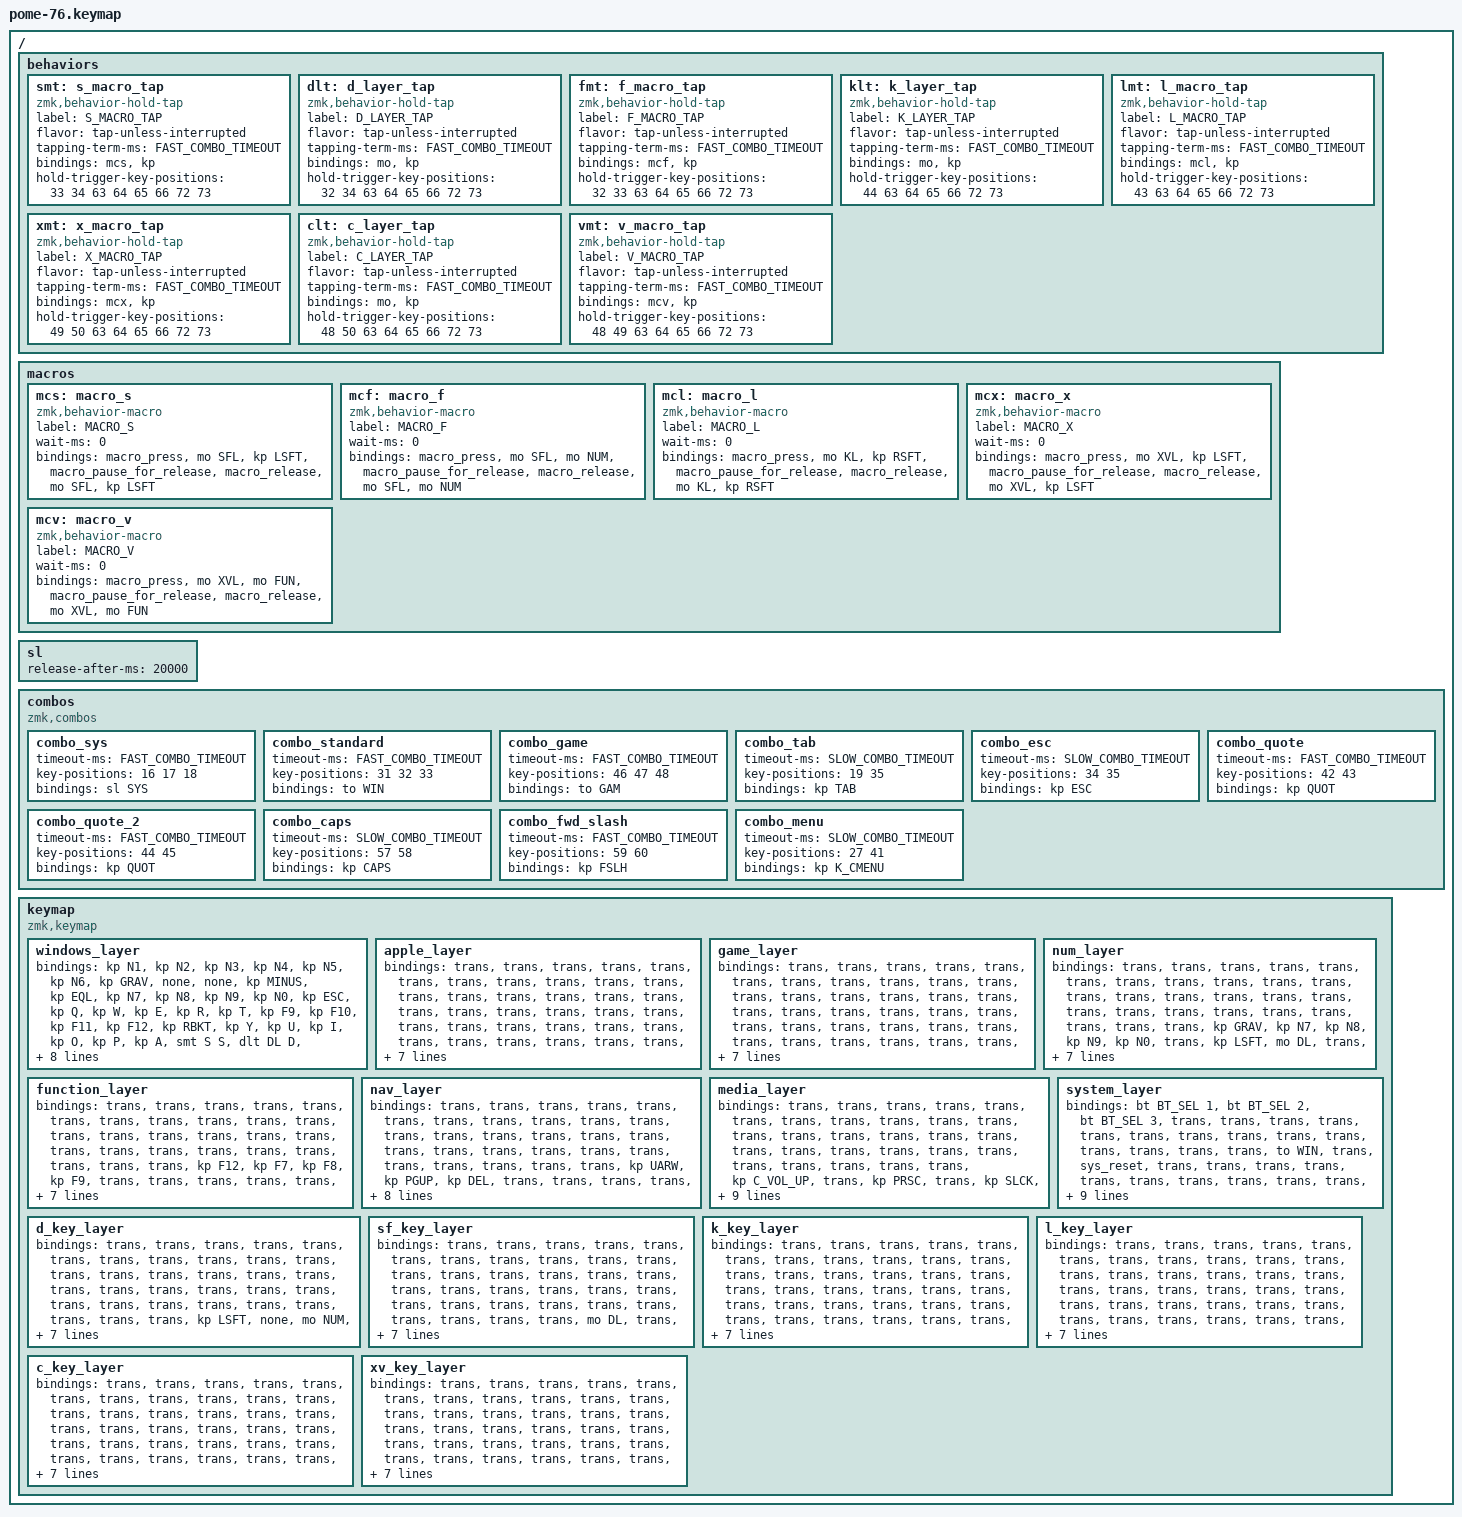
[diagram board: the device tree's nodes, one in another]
#include <behaviors.dtsi>
#include <dt-bindings/zmk/bt.h>
#include <dt-bindings/zmk/keys.h>
#include <dt-bindings/zmk/outputs.h>

// Layers ENUM
#define WIN 0     // Windows
#define APL 1     // Apple
#define GAM 2     // Gaming
#define NUM 3     // Numbers
#define FUN 4     // Function (F-keys)
#define NAV 5     // Navigation
#define MED 6     // Media
#define SYS 7     // System
#define DL  8     // D-Layer
#define SFL 9     // S/F-Layer
#define KL  10    // K-Layer
#define LL  11    // L-Layer
#define CL  12    // C-Layer
#define XVL 13    // X/V-Layer

// See mercury-u.keymap for the early history of timeout values.
// 12Nov2023
// The word "sounds" still rarely comes out as "soundSHIFT", so let's decrease timeout from 50ms to 35ms.
//#define FAST_COMBO_TIMEOUT 35
#define FAST_COMBO_TIMEOUT 1000 // for testing purposes only, extend this to a long time.

// #define MEDIUM_COMBO_TIMEOUT 125
#define MEDIUM_COMBO_TIMEOUT 80

// SLOW_COMBO_TIMEOUT is a very, very long and lenient timeout, and should be mostly only used for combos
// involving keys that are pressed by the same finger (H & J for example).
#define SLOW_COMBO_TIMEOUT 200

/ {
    behaviors {};

    macros {
        mcs: macro_s {
            label = "MACRO_S";
            compatible = "zmk,behavior-macro";
            #binding-cells = <0>;
            wait-ms = <0>;
            bindings
                = <&macro_press &mo SFL &kp LSFT>
                , <&macro_pause_for_release>
                , <&macro_release &mo SFL &kp LSFT>
                ;
        };

        mcf: macro_f {
            label = "MACRO_F";
            compatible = "zmk,behavior-macro";
            #binding-cells = <0>;
            wait-ms = <0>;
            bindings
                = <&macro_press &mo SFL &mo NUM>
                , <&macro_pause_for_release>
                , <&macro_release &mo SFL &mo NUM>
                ;
        };

        mcl: macro_l {
            label = "MACRO_L";
            compatible = "zmk,behavior-macro";
            #binding-cells = <0>;
            wait-ms = <0>;
            bindings
                = <&macro_press &mo KL &kp RSFT>
                , <&macro_pause_for_release>
                , <&macro_release &mo KL &kp RSFT>
                ;
        };

        mcx: macro_x {
            label = "MACRO_X";
            compatible = "zmk,behavior-macro";
            #binding-cells = <0>;
            wait-ms = <0>;
            bindings
                = <&macro_press &mo XVL &kp LSFT>
                , <&macro_pause_for_release>
                , <&macro_release &mo XVL &kp LSFT>
                ;
        };

        mcv: macro_v {
            label = "MACRO_V";
            compatible = "zmk,behavior-macro";
            #binding-cells = <0>;
            wait-ms = <0>;
            bindings
                = <&macro_press &mo XVL &mo FUN>
                , <&macro_pause_for_release>
                , <&macro_release &mo XVL &mo FUN>
                ;
        };
    };

    behaviors {
        // 63, 64, 65, and 66 are left hand modifier keys
        // 72 and 73 and right hand layer keys
        // 32 is S
        // 43 is K
        smt: s_macro_tap {
            compatible = "zmk,behavior-hold-tap";
            label = "S_MACRO_TAP";
            #binding-cells = <2>;
            flavor = "tap-unless-interrupted";
            tapping-term-ms = <FAST_COMBO_TIMEOUT>;
            bindings = <&mcs>, <&kp>;
            hold-trigger-key-positions = <33 34 63 64 65 66 72 73>;
        };

        dlt: d_layer_tap {
            compatible = "zmk,behavior-hold-tap";
            label = "D_LAYER_TAP";
            #binding-cells = <2>;
            flavor = "tap-unless-interrupted";
            tapping-term-ms = <FAST_COMBO_TIMEOUT>;
            bindings = <&mo>, <&kp>;
            hold-trigger-key-positions = <32 34 63 64 65 66 72 73>;
        };

        fmt: f_macro_tap {
            compatible = "zmk,behavior-hold-tap";
            label = "F_MACRO_TAP";
            #binding-cells = <2>;
            flavor = "tap-unless-interrupted";
            tapping-term-ms = <FAST_COMBO_TIMEOUT>;
            bindings = <&mcf>, <&kp>;
            hold-trigger-key-positions = <32 33 63 64 65 66 72 73>;
        };

        klt: k_layer_tap {
            compatible = "zmk,behavior-hold-tap";
            label = "K_LAYER_TAP";
            #binding-cells = <2>;
            flavor = "tap-unless-interrupted";
            tapping-term-ms = <FAST_COMBO_TIMEOUT>;
            bindings = <&mo>, <&kp>;
            hold-trigger-key-positions = <44 63 64 65 66 72 73>;
        };
        
        lmt: l_macro_tap {
            compatible = "zmk,behavior-hold-tap";
            label = "L_MACRO_TAP";
            #binding-cells = <2>;
            flavor = "tap-unless-interrupted";
            tapping-term-ms = <FAST_COMBO_TIMEOUT>;
            bindings = <&mcl>, <&kp>;
            hold-trigger-key-positions = <43 63 64 65 66 72 73>;
        };

        xmt: x_macro_tap {
            compatible = "zmk,behavior-hold-tap";
            label = "X_MACRO_TAP";
            #binding-cells = <2>;
            flavor = "tap-unless-interrupted";
            tapping-term-ms = <FAST_COMBO_TIMEOUT>;
            bindings = <&mcx>, <&kp>;
            hold-trigger-key-positions = <49 50 63 64 65 66 72 73>;
        };

        clt: c_layer_tap {
            compatible = "zmk,behavior-hold-tap";
            label = "C_LAYER_TAP";
            #binding-cells = <2>;
            flavor = "tap-unless-interrupted";
            tapping-term-ms = <FAST_COMBO_TIMEOUT>;
            bindings = <&mo>, <&kp>;
            hold-trigger-key-positions = <48 50 63 64 65 66 72 73>;
        };

        vmt: v_macro_tap {
            compatible = "zmk,behavior-hold-tap";
            label = "V_MACRO_TAP";
            #binding-cells = <2>;
            flavor = "tap-unless-interrupted";
            tapping-term-ms = <FAST_COMBO_TIMEOUT>;
            bindings = <&mcv>, <&kp>;
            hold-trigger-key-positions = <48 49 63 64 65 66 72 73>;
        };
    };

    sl {
        release-after-ms = <20000>; // 20 seconds
    };
    combos {
        compatible = "zmk,combos";

        combo_sys {
            timeout-ms = <FAST_COMBO_TIMEOUT>;
            key-positions = <16 17 18>;
            bindings = <&sl SYS>;
        };
        combo_standard {
            timeout-ms = <FAST_COMBO_TIMEOUT>;
            key-positions = <31 32 33>;
            bindings = <&to WIN>;
        };
        combo_game {
            timeout-ms = <FAST_COMBO_TIMEOUT>;
            key-positions = <46 47 48>;
            bindings = <&to GAM>;
        };

        // Slow combos: these combos exclusively use keys controlled by a single index-finger,
        // which makes them very unlikely to be accidentally triggered by a standard touch-typist
        // them during normal typing, even with a very long timeout.
        combo_tab {
            timeout-ms = <SLOW_COMBO_TIMEOUT>;
            key-positions = <19 35>; /* RG */
            bindings = <&kp TAB>;
        };
        combo_esc {
            timeout-ms = <SLOW_COMBO_TIMEOUT>;
            key-positions = <34 35>; /* FG */
            bindings = <&kp ESC>;
        };
        combo_quote {
            timeout-ms = <FAST_COMBO_TIMEOUT>;
            key-positions = <42 43>; /* JK */
            bindings = <&kp QUOT>;
        };
        combo_quote_2 {
            timeout-ms = <FAST_COMBO_TIMEOUT>;
            key-positions = <44 45>; /* L; */
            bindings = <&kp QUOT>;
        };
        combo_caps {
            timeout-ms = <SLOW_COMBO_TIMEOUT>;
            key-positions = <57 58>; /* NM */
            bindings = <&kp CAPS>;
        };
        combo_fwd_slash {
            timeout-ms = <FAST_COMBO_TIMEOUT>;
            // HU is a little hard to reach */
            key-positions = <59 60>; /* ,. */
            bindings = <&kp FSLH>;
        };
        combo_menu {
            timeout-ms = <SLOW_COMBO_TIMEOUT>;
            key-positions = <27 41>; /* UH */
            bindings = <&kp K_CMENU>;
        };
    };

    keymap {
        compatible = "zmk,keymap";

        windows_layer {
            bindings = <
              &kp N1        &kp N2        &kp N3        &kp N4        &kp N5        &kp N6        &kp GRAV      &none         &none         &kp MINUS     &kp EQL       &kp N7        &kp N8        &kp N9        &kp N0        &kp ESC
              &kp Q         &kp W         &kp E         &kp R         &kp T         &kp F9        &kp F10       &kp F11       &kp F12       &kp RBKT      &kp Y         &kp U         &kp I         &kp O         &kp P
              &kp A         &smt S S      &dlt DL D     &fmt F F      &kp G         &kp F5        &kp F6        &kp F7        &kp F8        &kp LBKT      &kp H         &kp J         &klt KL K     &lmt L L      &kp SCLN
&kp LSFT      &kp Z         &xmt X X      &clt CL C     &vmt V V      &kp B         &kp F1        &kp F2        &kp F3        &kp F4        &kp BSLH      &kp N         &kp M         &kp CMMA      &kp DOT
&kp ESC       &kp DEL       &kp LGUI      &none        &kp LCTL      &kp LALT      &none         &none         &none         &kp BSLH      &kp SPC       &mo NAV       &mo MED       &kp BKSP      &kp RET
            >;
        };
        
        apple_layer {
            bindings = <
              &trans        &trans        &trans        &trans        &trans        &trans        &trans        &trans        &trans        &trans        &trans        &trans        &trans        &trans        &trans        &trans
              &trans        &trans        &trans        &trans        &trans        &trans        &trans        &trans        &trans        &trans        &trans        &trans        &trans        &trans        &trans
              &trans        &trans        &trans        &trans        &trans        &trans        &trans        &trans        &trans        &trans        &trans        &trans        &trans        &trans        &trans
&trans        &trans        &trans        &trans        &trans        &trans        &trans        &trans        &trans        &trans        &trans        &trans        &trans        &trans        &trans
&trans        &trans        &trans        &kp LCTL      &kp LGUI      &kp LALT      &trans        &trans        &trans        &trans        &trans        &trans        &trans        &trans        &trans
            >;
        };

// game_layer is disabled (fully transparent) for now.
        game_layer {
            bindings = <
              &trans        &trans        &trans        &trans        &trans        &trans        &trans        &trans        &trans        &trans        &trans        &trans        &trans        &trans        &trans        &trans
              &trans        &trans        &trans        &trans        &trans        &trans        &trans        &trans        &trans        &trans        &trans        &trans        &trans        &trans        &trans
              &trans        &trans        &trans        &trans        &trans        &trans        &trans        &trans        &trans        &trans        &trans        &trans        &trans        &trans        &trans
&trans        &trans        &trans        &trans        &trans        &trans        &trans        &trans        &trans        &trans        &trans        &trans        &trans        &trans        &trans
&trans        &trans        &trans        &trans        &trans        &trans        &trans        &trans        &trans        &trans        &trans        &trans        &trans        &trans        &trans
            >;
        };

        num_layer {
            bindings = <
              &trans        &trans        &trans        &trans        &trans        &trans        &trans        &trans        &trans        &trans        &trans        &trans        &trans        &trans        &trans        &trans
              &trans        &trans        &trans        &trans        &trans        &trans        &trans        &trans        &trans        &trans        &kp GRAV      &kp N7        &kp N8        &kp N9        &kp N0
              &trans        &kp LSFT      &mo DL        &trans        &trans        &trans        &trans        &trans        &trans        &trans        &kp EQL       &kp N4        &kp N5        &kp N6        &kp DOT
&trans        &trans        &trans        &trans        &trans        &trans        &trans        &trans        &trans        &trans        &trans        &kp MINUS     &kp N1        &kp N2        &kp N3
&trans        &trans        &trans        &trans        &trans        &trans        &trans        &trans        &trans        &trans        &kp SPC       &mo NAV       &mo MED       &trans        &trans

            >;
        };

        function_layer {
            bindings = <
              &trans        &trans        &trans        &trans        &trans        &trans        &trans        &trans        &trans        &trans        &trans        &trans        &trans        &trans        &trans        &trans
              &trans        &trans        &trans        &trans        &trans        &trans        &trans        &trans        &trans        &trans        &kp F12       &kp F7        &kp F8        &kp F9        &trans
              &trans        &trans        &trans        &trans        &trans        &trans        &trans        &trans        &trans        &trans        &kp F11       &kp F4        &kp F5        &kp F6        &trans
&trans        &trans        &kp LSFT      &mo CL        &trans        &trans        &trans        &trans        &trans        &trans        &trans        &kp F10       &kp F1        &kp F2        &kp F3
&trans        &trans        &trans        &trans        &trans        &trans        &trans        &trans        &trans        &trans        &trans        &trans        &trans        &trans        &trans

            >;
        };

        nav_layer {
            bindings = <
              &trans        &trans        &trans        &trans        &trans        &trans        &trans        &trans        &trans        &trans        &trans        &trans        &trans        &trans        &trans        &trans
              &trans        &trans        &trans        &trans        &trans        &trans        &trans        &trans        &trans        &trans        &trans        &trans        &kp UARW      &kp PGUP      &kp DEL
              &trans        &trans        &trans        &trans        &trans        &trans        &trans        &trans        &trans        &trans        &trans        &kp LARW      &kp DARW      &kp RARW      &kp BKSP
&trans        &trans        &trans        &trans        &trans        &trans        &trans        &trans        &trans        &trans        &trans        &kp PGDN      &kp HOME      &kp END       &kp RET
&trans        &trans        &trans        &trans        &trans        &trans        &trans        &trans        &trans        &trans        &trans        &trans        &trans        &trans        &trans
            >;
        };

        media_layer {
            bindings = <
              &trans        &trans        &trans        &trans        &trans        &trans        &trans        &trans        &trans        &trans        &trans        &trans        &trans        &trans        &trans        &trans
              &trans        &trans        &trans        &trans        &trans        &trans        &trans        &trans        &trans        &trans        &trans        &trans        &kp C_VOL_UP  &trans        &kp PRSC
              &trans        &kp SLCK      &trans        &trans        &trans        &trans        &trans        &trans        &trans        &trans        &trans        &kp C_BRI_DN  &kp C_VOL_DN  &kp C_BRI_UP  &trans
&trans        &trans        &trans        &trans        &trans    &kp PAUSE_BREAK   &trans        &trans        &trans        &trans        &trans        &trans        &kp INS       &kp C_MUTE    &trans
&trans        &trans        &trans        &trans        &trans        &trans        &trans        &trans        &trans        &trans        &trans        &trans        &trans        &trans        &trans

            >;
        };

        system_layer {
            bindings = <
              &bt BT_SEL 1  &bt BT_SEL 2  &bt BT_SEL 3  &trans        &trans        &trans        &trans        &trans        &trans        &trans        &trans        &trans        &trans        &trans        &trans        &trans
              &trans        &to WIN       &trans        &sys_reset    &trans        &trans        &trans        &trans        &trans        &trans        &trans        &trans        &trans        &trans        &trans
              &to APL       &out OUT_USB  &trans        &bootloader   &trans        &trans        &trans        &trans        &trans        &trans        &trans        &trans        &trans        &trans        &trans
&trans        &trans        &trans        &bt BT_CLR    &trans        &out OUT_BLE  &trans        &trans        &trans        &trans        &trans        &trans        &trans        &trans        &trans
&trans        &trans        &trans        &trans        &trans        &trans        &trans        &trans        &trans        &trans        &trans        &trans        &trans        &trans        &trans
            >;
        };

        d_key_layer {
            bindings = <
              &trans        &trans        &trans        &trans        &trans        &trans        &trans        &trans        &trans        &trans        &trans        &trans        &trans        &trans        &trans        &trans
              &trans        &trans        &trans        &trans        &trans        &trans        &trans        &trans        &trans        &trans        &trans        &trans        &trans        &trans        &trans
              &trans        &kp LSFT      &none         &mo NUM       &trans        &trans        &trans        &trans        &trans        &trans        &trans        &trans        &trans        &trans        &trans
&trans        &trans        &trans        &trans        &trans        &trans        &trans        &trans        &trans        &trans        &trans        &trans        &trans        &trans        &trans
&trans        &trans        &trans        &trans        &trans        &trans        &trans        &trans        &trans        &trans        &trans        &trans        &trans        &trans        &trans
            >;
        };

        sf_key_layer {
            bindings = <
              &trans        &trans        &trans        &trans        &trans        &trans        &trans        &trans        &trans        &trans        &trans        &trans        &trans        &trans        &trans        &trans
              &trans        &trans        &trans        &trans        &trans        &trans        &trans        &trans        &trans        &trans        &trans        &trans        &trans        &trans        &trans
              &trans        &trans        &mo DL        &trans        &trans        &trans        &trans        &trans        &trans        &trans        &trans        &trans        &trans        &trans        &trans
&trans        &trans        &trans        &trans        &trans        &trans        &trans        &trans        &trans        &trans        &trans        &trans        &trans        &trans        &trans
&trans        &trans        &trans        &trans        &trans        &trans        &trans        &trans        &trans        &trans        &trans        &trans        &trans        &trans        &trans
            >;
        };

        k_key_layer {
            bindings = <
              &trans        &trans        &trans        &trans        &trans        &trans        &trans        &trans        &trans        &trans        &trans        &trans        &trans        &trans        &trans        &trans
              &trans        &trans        &trans        &trans        &trans        &trans        &trans        &trans        &trans        &trans        &trans        &trans        &trans        &trans        &trans
              &trans        &trans        &trans        &trans        &trans        &trans        &trans        &trans        &trans        &trans        &trans        &trans        &none         &kp RSFT      &trans
&trans        &trans        &trans        &trans        &trans        &trans        &trans        &trans        &trans        &trans        &trans        &trans        &trans        &trans        &trans
&trans        &trans        &trans        &trans        &trans        &trans        &trans        &trans        &trans        &trans        &trans        &trans        &trans        &trans        &trans
            >;
        };

        l_key_layer {
            bindings = <
              &trans        &trans        &trans        &trans        &trans        &trans        &trans        &trans        &trans        &trans        &trans        &trans        &trans        &trans        &trans        &trans
              &trans        &trans        &trans        &trans        &trans        &trans        &trans        &trans        &trans        &trans        &trans        &trans        &trans        &trans        &trans
              &trans        &trans        &trans        &trans        &trans        &trans        &trans        &trans        &trans        &trans        &trans        &trans        &mo KL        &trans        &trans
&trans        &trans        &trans        &trans        &trans        &trans        &trans        &trans        &trans        &trans        &trans        &trans        &trans        &trans        &trans
&trans        &trans        &trans        &trans        &trans        &trans        &trans        &trans        &trans        &trans        &trans        &trans        &trans        &trans        &trans
            >;
        };

        c_key_layer {
            bindings = <
              &trans        &trans        &trans        &trans        &trans        &trans        &trans        &trans        &trans        &trans        &trans        &trans        &trans        &trans        &trans        &trans
              &trans        &trans        &trans        &trans        &trans        &trans        &trans        &trans        &trans        &trans        &trans        &trans        &trans        &trans        &trans
              &trans        &trans        &trans        &trans        &trans        &trans        &trans        &trans        &trans        &trans        &trans        &trans        &trans        &trans        &trans
&trans        &trans        &kp LSFT      &none         &mo FUN       &trans        &trans        &trans        &trans        &trans        &trans        &trans        &trans        &trans        &trans
&trans        &trans        &trans        &trans        &trans        &trans        &trans        &trans        &trans        &trans        &trans        &trans        &trans        &trans        &trans
            >;
        };

        xv_key_layer {
            bindings = <
              &trans        &trans        &trans        &trans        &trans        &trans        &trans        &trans        &trans        &trans        &trans        &trans        &trans        &trans        &trans        &trans
              &trans        &trans        &trans        &trans        &trans        &trans        &trans        &trans        &trans        &trans        &trans        &trans        &trans        &trans        &trans
              &trans        &trans        &trans        &trans        &trans        &trans        &trans        &trans        &trans        &trans        &trans        &trans        &trans        &trans        &trans
&trans        &trans        &trans        &mo CL        &trans        &trans        &trans        &trans        &trans        &trans        &trans        &trans        &trans        &trans        &trans
&trans        &trans        &trans        &trans        &trans        &trans        &trans        &trans        &trans        &trans        &trans        &trans        &trans        &trans        &trans
            >;
        };
    };
};
